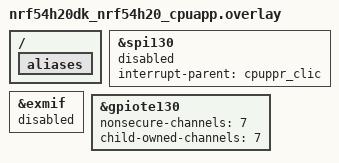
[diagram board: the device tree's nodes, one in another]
/*
 * Copyright (c) 2025 Nordic Semiconductor ASA
 *
 * SPDX-License-Identifier: LicenseRef-Nordic-5-Clause
 */

/ {
	aliases {
		/delete-property/ led0;
		/delete-property/ led1;
		/delete-property/ mcuboot-led0;
	};
};

/delete-node/ &led0;
/delete-node/ &led1;

&spi130 {
	 status = "reserved";
	 interrupt-parent = <&cpuppr_clic>;
};

&exmif {
	status = "disabled";
};

&gpiote130 {
	nonsecure-channels = <7>;
	child-owned-channels = <7>;
};
